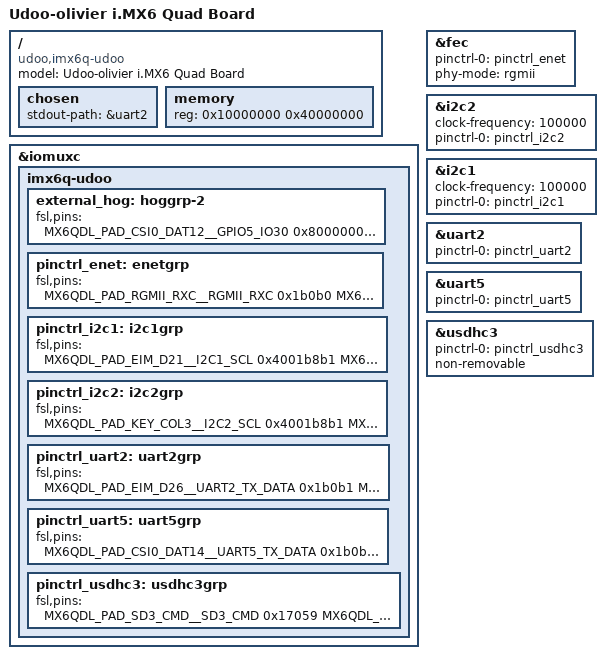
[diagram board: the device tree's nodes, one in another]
/*
 * Copyright 2013 Freescale Semiconductor, Inc.
 *
 * Author: Fabio Estevam <fabio.estevam@freescale.com>
 *
 * This program is free software; you can redistribute it and/or modify
 * it under the terms of the GNU General Public License version 2 as
 * published by the Free Software Foundation.
 *
 */

/dts-v1/;
#include "imx6q.dtsi"

/ {
	model = "Udoo-olivier i.MX6 Quad Board";
	compatible = "udoo,imx6q-udoo", "fsl,imx6q";

	chosen {
		stdout-path = &uart2;
	};

	memory {
		reg = <0x10000000 0x40000000>;
	};
};

&iomuxc {
	imx6q-udoo {

		// External Pinout GPIOs
        external_hog: hoggrp-2 {
        fsl,pins = <
            MX6QDL_PAD_CSI0_DAT12__GPIO5_IO30    0x80000000  // {{external-gpio-18}}
            MX6QDL_PAD_NANDF_D3__GPIO2_IO03      0x80000000  // {{external-gpio-41}} (SEARCH)
            MX6QDL_PAD_NANDF_D2__GPIO2_IO02      0x80000000  // {{external-gpio-42}} (BACK)
            >;
        };
		
		pinctrl_enet: enetgrp {
			fsl,pins = <
				MX6QDL_PAD_RGMII_RXC__RGMII_RXC		0x1b0b0
				MX6QDL_PAD_RGMII_RD0__RGMII_RD0		0x1b0b0
				MX6QDL_PAD_RGMII_RD1__RGMII_RD1		0x1b0b0
				MX6QDL_PAD_RGMII_RD2__RGMII_RD2		0x1b0b0
				MX6QDL_PAD_RGMII_RD3__RGMII_RD3		0x1b0b0
				MX6QDL_PAD_RGMII_RX_CTL__RGMII_RX_CTL	0x1b0b0
				MX6QDL_PAD_RGMII_TXC__RGMII_TXC		0x1b0b0
				MX6QDL_PAD_RGMII_TD0__RGMII_TD0		0x1b0b0
				MX6QDL_PAD_RGMII_TD1__RGMII_TD1		0x1b0b0
				MX6QDL_PAD_RGMII_TD2__RGMII_TD2		0x1b0b0
				MX6QDL_PAD_RGMII_TD3__RGMII_TD3		0x1b0b0
				MX6QDL_PAD_RGMII_TX_CTL__RGMII_TX_CTL	0x1b0b0
				MX6QDL_PAD_ENET_REF_CLK__ENET_TX_CLK	0x1b0b0
				MX6QDL_PAD_ENET_MDIO__ENET_MDIO		0x1b0b0
				MX6QDL_PAD_ENET_MDC__ENET_MDC		0x1b0b0
				MX6QDL_PAD_GPIO_16__ENET_REF_CLK	0x4001b0a8
			>;
		};

		// I2c1 = external i2c
		pinctrl_i2c1: i2c1grp {
			fsl,pins = <
			MX6QDL_PAD_EIM_D21__I2C1_SCL		0x4001b8b1
			MX6QDL_PAD_EIM_D28__I2C1_SDA		0x4001b8b1
			>;
		};

		// I2c2
		pinctrl_i2c2: i2c2grp {
			fsl,pins = <
				MX6QDL_PAD_KEY_COL3__I2C2_SCL		0x4001b8b1
				MX6QDL_PAD_KEY_ROW3__I2C2_SDA		0x4001b8b1
			>;
		};


		// Debug uart via ftdi-usb
		pinctrl_uart2: uart2grp {
			fsl,pins = <
				MX6QDL_PAD_EIM_D26__UART2_TX_DATA	0x1b0b1
				MX6QDL_PAD_EIM_D27__UART2_RX_DATA	0x1b0b1
			>;
		};

		// External uart 
		pinctrl_uart5: uart5grp {
		    fsl,pins = <
		    MX6QDL_PAD_CSI0_DAT14__UART5_TX_DATA      0x1b0b1
		    MX6QDL_PAD_CSI0_DAT15__UART5_RX_DATA      0x1b0b1
		    >;
		};

		// Sd-interface
		pinctrl_usdhc3: usdhc3grp {
			fsl,pins = <
				MX6QDL_PAD_SD3_CMD__SD3_CMD		0x17059
				MX6QDL_PAD_SD3_CLK__SD3_CLK		0x10059
				MX6QDL_PAD_SD3_DAT0__SD3_DATA0		0x17059
				MX6QDL_PAD_SD3_DAT1__SD3_DATA1		0x17059
				MX6QDL_PAD_SD3_DAT2__SD3_DATA2		0x17059
				MX6QDL_PAD_SD3_DAT3__SD3_DATA3		0x17059
			>;
		};
	};
};

// &sata {
// 	status = "okay";
// };

&fec {
	pinctrl-names = "default";
	pinctrl-0 = <&pinctrl_enet>;
	phy-mode = "rgmii";
	status = "okay";
};

// &hdmi {
// 	ddc-i2c-bus = <&i2c2>;
// 	status = "okay";
// };

&i2c2 {
	clock-frequency = <100000>;
	pinctrl-names = "default";
	pinctrl-0 = <&pinctrl_i2c2>;
	status = "okay";
};

&i2c1 {
	clock-frequency = <100000>;
	pinctrl-names = "default";
	pinctrl-0 = <&pinctrl_i2c1>;
	status = "okay";
};

&uart2 {
	pinctrl-names = "default";
	pinctrl-0 = <&pinctrl_uart2>;
	status = "okay";
};

&uart5 {
	pinctrl-names = "default";
	pinctrl-0 = <&pinctrl_uart5>;
	status = "okay";
};

&usdhc3 {
	pinctrl-names = "default";
	pinctrl-0 = <&pinctrl_usdhc3>;
	non-removable;
	status = "okay";
};
